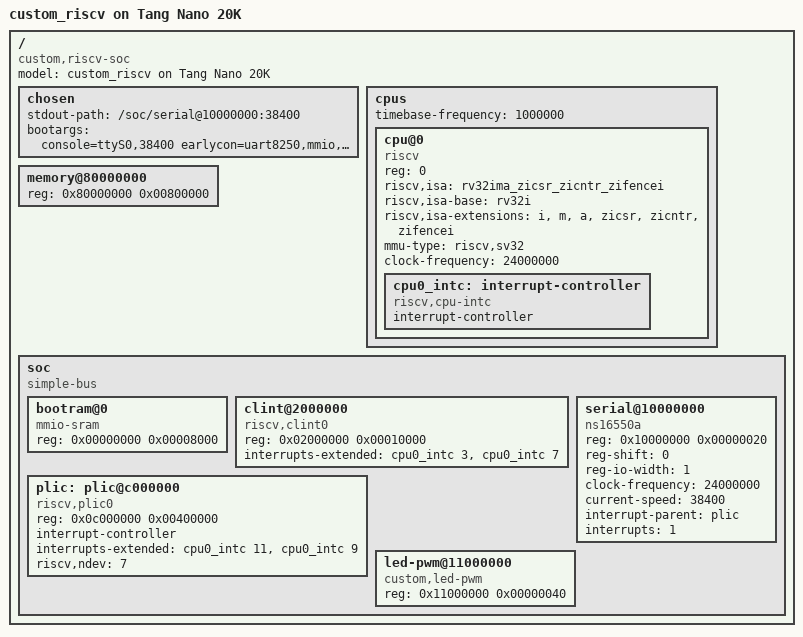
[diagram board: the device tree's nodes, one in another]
/dts-v1/;

/*
 * Device tree for the custom_riscv SoC.
 *
 * This is how OpenSBI and Linux learn the layout, and it is the reason the base
 * addresses in wb_defines.vh were free to choose in the first place: nothing in
 * the software stack has them compiled in, it reads them from here. The offsets
 * *inside* the CLINT and the PLIC are a different matter - those are fixed by
 * their specifications, and this file only says where each block starts.
 *
 * Two values here are easy to get wrong and hard to debug:
 *
 *   timebase-frequency  must be the rate mtime actually ticks, which is 1 MHz
 *                       from the CLINT's prescaler - NOT the CPU clock. Get it
 *                       wrong and every timeout in the OS is wrong by that
 *                       ratio, which looks like a hang rather than a bad number.
 *   clock-frequency on the UART is its *input* clock, 24 MHz. The driver
 *                       divides it down itself, so this is not the baud rate.
 */

/ {
	#address-cells = <1>;
	#size-cells = <1>;
	compatible = "custom,riscv-soc";
	model = "custom_riscv on Tang Nano 20K";

	chosen {
		stdout-path = "/soc/serial@10000000:38400";
		/*
		 * earlycon matters more than it looks: without it nothing is
		 * printed between the kernel's first instruction and the 8250
		 * driver probing, which is most of what can go wrong on a new
		 * machine. rootwait/root are left out - see the initrd note in
		 * the Linux boot targets.
		 */
		bootargs = "console=ttyS0,38400 earlycon=uart8250,mmio,0x10000000,38400 loglevel=8";
	};

	cpus {
		#address-cells = <1>;
		#size-cells = <0>;
		timebase-frequency = <1000000>;		/* CLINT mtime, 1 MHz */

		cpu@0 {
			device_type = "cpu";
			compatible = "riscv";
			reg = <0>;
			riscv,isa = "rv32ima_zicsr_zicntr_zifencei";
			riscv,isa-base = "rv32i";
			riscv,isa-extensions = "i", "m", "a", "zicsr", "zicntr", "zifencei";
			/*
			 * Deliberately absent: "c". This core has no compressed
			 * instructions, so a kernel or libc built with them
			 * faults on the first one - which looks like a crash at
			 * a random address rather than a missing extension.
			 */
			mmu-type = "riscv,sv32";	/* two-level, 4 KB and 4 MB pages */
			clock-frequency = <24000000>;
			status = "okay";

			cpu0_intc: interrupt-controller {
				compatible = "riscv,cpu-intc";
				interrupt-controller;
				#interrupt-cells = <1>;
			};
		};
	};

	/* 8 MB of SDRAM in the GW2AR-18 package. */
	memory@80000000 {
		device_type = "memory";
		reg = <0x80000000 0x00800000>;
	};

	soc {
		compatible = "simple-bus";
		#address-cells = <1>;
		#size-cells = <1>;
		ranges;

		/* 32 KB of FPGA block RAM at the reset vector, holding the BIOS. */
		bootram@0 {
			compatible = "mmio-sram";
			reg = <0x00000000 0x00008000>;
		};

		clint@2000000 {
			compatible = "riscv,clint0";
			reg = <0x02000000 0x00010000>;
			interrupts-extended = <&cpu0_intc 3 &cpu0_intc 7>;
		};

		plic: plic@c000000 {
			compatible = "riscv,plic0";
			reg = <0x0c000000 0x00400000>;
			interrupt-controller;
			#interrupt-cells = <1>;
			#address-cells = <0>;
			/*
			 * Both contexts, in the order the binding requires:
			 * context 0 is hart 0 machine mode, context 1 is hart 0
			 * supervisor mode. Linux drives the supervisor one, and
			 * with only the machine entry here it finds no context
			 * of its own and every device interrupt goes nowhere.
			 */
			interrupts-extended = <&cpu0_intc 11 &cpu0_intc 9>;
			riscv,ndev = <7>;
		};

		/*
		 * OpenCores 16550. Byte addressed - register N sits at base + N -
		 * so reg-shift is 0 and reg-io-width is 1.
		 */
		serial@10000000 {
			compatible = "ns16550a";
			reg = <0x10000000 0x00000020>;
			reg-shift = <0>;
			reg-io-width = <1>;
			clock-frequency = <24000000>;
			current-speed = <38400>;
			interrupt-parent = <&plic>;
			interrupts = <1>;
			status = "okay";
		};

		/*
		 * Our own device: six PWM channels plus a software-interrupt
		 * trigger register at +0x20. No standard binding, so it is
		 * described only so the address is not silently reused.
		 */
		led-pwm@11000000 {
			compatible = "custom,led-pwm";
			reg = <0x11000000 0x00000040>;
			status = "okay";
		};
	};
};
